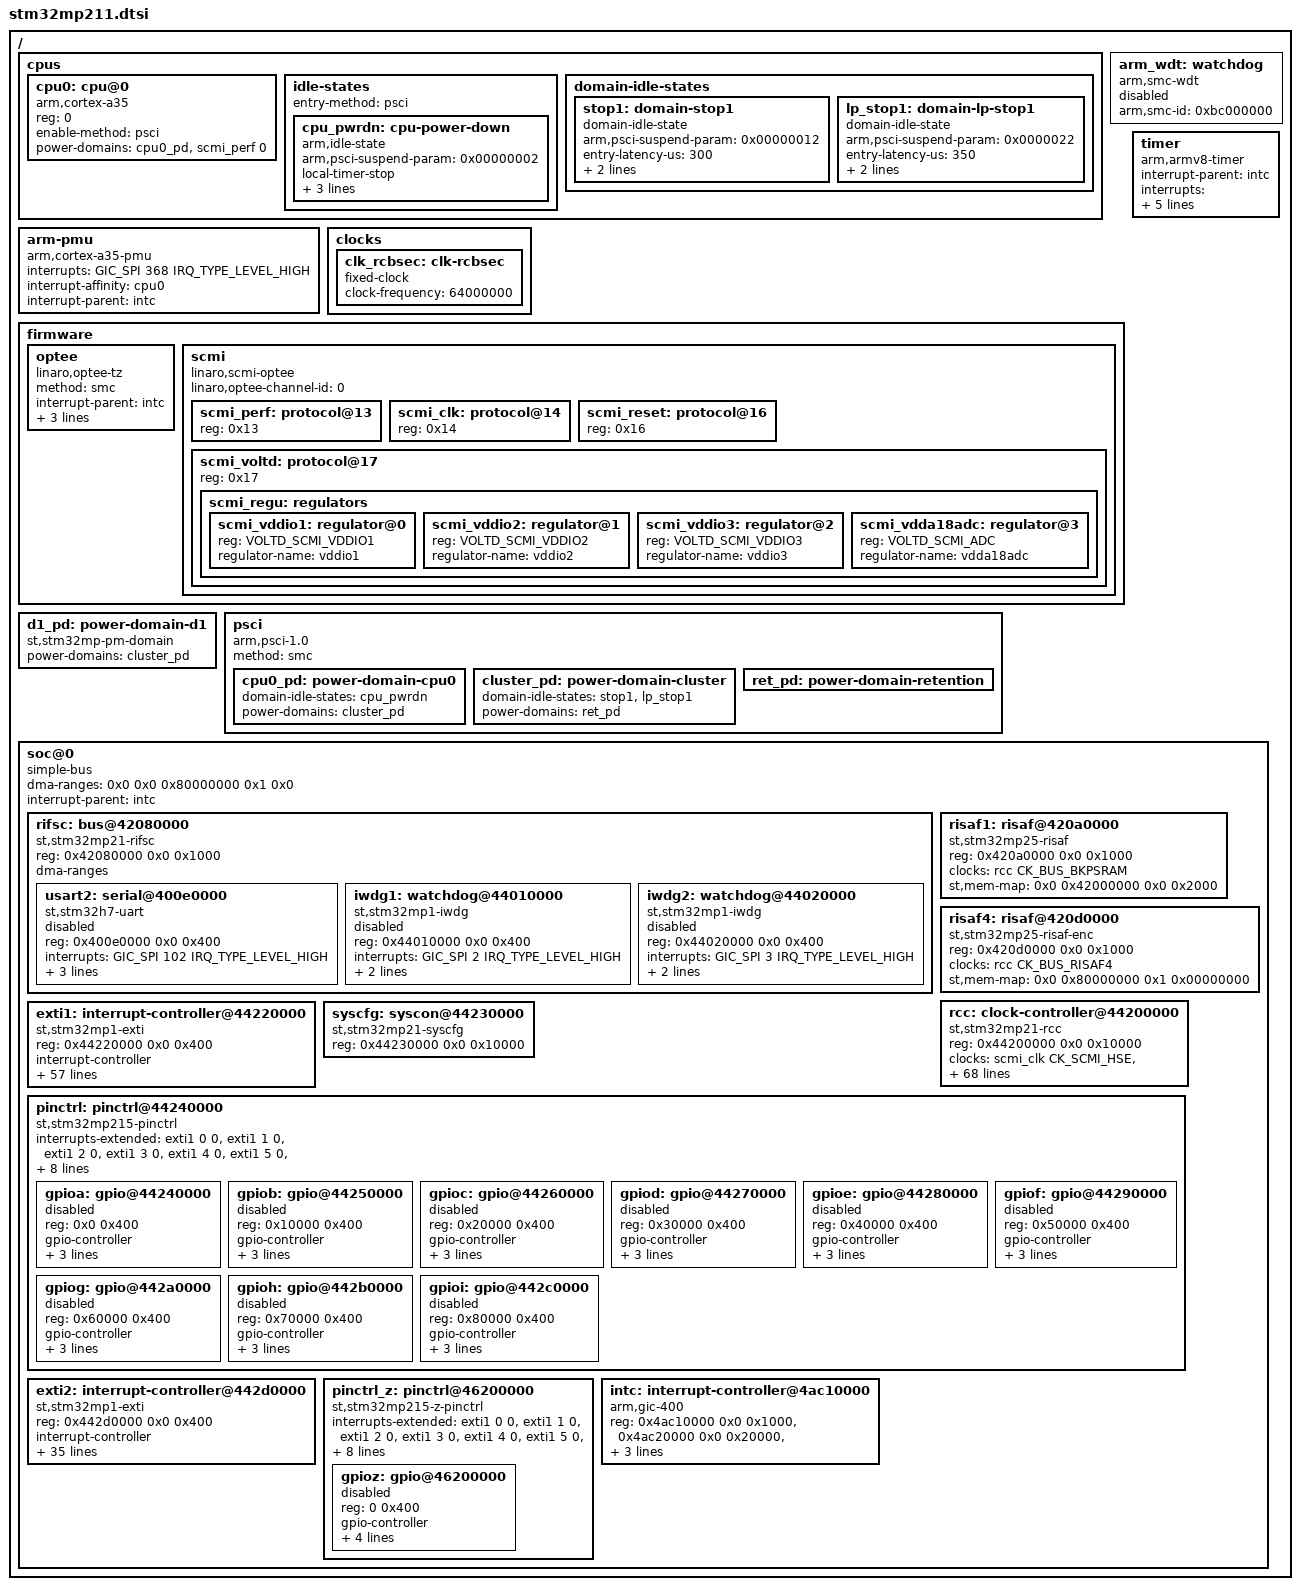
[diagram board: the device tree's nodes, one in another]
// SPDX-License-Identifier: (GPL-2.0-only OR BSD-3-Clause)
/*
 * Copyright (C) STMicroelectronics 2025 - All Rights Reserved
 * Author: Alexandre Torgue <alexandre.torgue@foss.st.com> for STMicroelectronics.
 */
#include <dt-bindings/clock/st,stm32mp21-rcc.h>
#include <dt-bindings/interrupt-controller/arm-gic.h>
#include <dt-bindings/regulator/st,stm32mp21-regulator.h>
#include <dt-bindings/reset/st,stm32mp21-rcc.h>

/ {
	#address-cells = <2>;
	#size-cells = <2>;

	cpus {
		#address-cells = <1>;
		#size-cells = <0>;

		cpu0: cpu@0 {
			compatible = "arm,cortex-a35";
			reg = <0>;
			device_type = "cpu";
			enable-method = "psci";
			power-domains = <&cpu0_pd>, <&scmi_perf 0>;
			power-domain-names = "psci", "perf";
		};

		idle-states {
			entry-method = "psci";

			cpu_pwrdn: cpu-power-down {

				compatible = "arm,idle-state";
				arm,psci-suspend-param = <0x00000002>;
				local-timer-stop;
				entry-latency-us = <150>;
				exit-latency-us = <200>;
				min-residency-us = <1000>;
			};
		};

		domain-idle-states {
			stop1: domain-stop1 {
				compatible = "domain-idle-state";
				arm,psci-suspend-param = <0x00000012>;
				entry-latency-us = <300>;
				exit-latency-us = <500>;
				min-residency-us = <1500>;
			};

			lp_stop1: domain-lp-stop1 {
				compatible = "domain-idle-state";
				arm,psci-suspend-param = <0x0000022>;
				entry-latency-us = <350>;
				exit-latency-us = <600>;
				min-residency-us = <2000>;
			};
		};
	};

	arm-pmu {
		compatible = "arm,cortex-a35-pmu";
		interrupts = <GIC_SPI 368 IRQ_TYPE_LEVEL_HIGH>;
		interrupt-affinity = <&cpu0>;
		interrupt-parent = <&intc>;
	};

	arm_wdt: watchdog {
		compatible = "arm,smc-wdt";
		arm,smc-id = <0xbc000000>;
		status = "disabled";
	};

	clocks {
		clk_rcbsec: clk-rcbsec {
			#clock-cells = <0>;
			compatible = "fixed-clock";
			clock-frequency = <64000000>;
		};
	};

	firmware {
		optee: optee {
			compatible = "linaro,optee-tz";
			method = "smc";
			interrupt-parent = <&intc>;
			interrupts = <GIC_PPI 15 (GIC_CPU_MASK_SIMPLE(1) | IRQ_TYPE_LEVEL_LOW)>;
			interrupt-controller;
			#interrupt-cells = <1>;
		};

		scmi: scmi {
			compatible = "linaro,scmi-optee";
			#address-cells = <1>;
			#size-cells = <0>;
			linaro,optee-channel-id = <0>;

			scmi_perf: protocol@13 {
				reg = <0x13>;
				#power-domain-cells = <1>;
			};

			scmi_clk: protocol@14 {
				reg = <0x14>;
				#clock-cells = <1>;
			};

			scmi_reset: protocol@16 {
				reg = <0x16>;
				#reset-cells = <1>;
			};

			scmi_voltd: protocol@17 {
				reg = <0x17>;

				scmi_regu: regulators {
					#address-cells = <1>;
					#size-cells = <0>;

					scmi_vddio1: regulator@0 {
						reg = <VOLTD_SCMI_VDDIO1>;
						regulator-name = "vddio1";
					};
					scmi_vddio2: regulator@1 {
						reg = <VOLTD_SCMI_VDDIO2>;
						regulator-name = "vddio2";
					};
					scmi_vddio3: regulator@2 {
						reg = <VOLTD_SCMI_VDDIO3>;
						regulator-name = "vddio3";
					};
					scmi_vdda18adc: regulator@3 {
						reg = <VOLTD_SCMI_ADC>;
						regulator-name = "vdda18adc";
					};
				};
			};
		};
	};

	d1_pd: power-domain-d1 {
		compatible = "st,stm32mp-pm-domain";
		#power-domain-cells = <0>;
		power-domains = <&cluster_pd>;
	};

	psci: psci {
		compatible = "arm,psci-1.0";
		method = "smc";

		cpu0_pd: power-domain-cpu0 {
			#power-domain-cells = <0>;
			domain-idle-states = <&cpu_pwrdn>;
			power-domains = <&cluster_pd>;
		};

		cluster_pd: power-domain-cluster {
			#power-domain-cells = <0>;
			domain-idle-states = <&stop1>, <&lp_stop1>;
			power-domains = <&ret_pd>;
		};

		ret_pd: power-domain-retention {
			#power-domain-cells = <0>;
		};
	};

	timer {
		compatible = "arm,armv8-timer";
		interrupt-parent = <&intc>;
		interrupts = <GIC_PPI 13 (GIC_CPU_MASK_SIMPLE(1) | IRQ_TYPE_LEVEL_LOW)>,
			     <GIC_PPI 14 (GIC_CPU_MASK_SIMPLE(1) | IRQ_TYPE_LEVEL_LOW)>,
			     <GIC_PPI 11 (GIC_CPU_MASK_SIMPLE(1) | IRQ_TYPE_LEVEL_LOW)>,
			     <GIC_PPI 10 (GIC_CPU_MASK_SIMPLE(1) | IRQ_TYPE_LEVEL_LOW)>;
		arm,no-tick-in-suspend;
	};

	soc@0 {
		compatible = "simple-bus";
		ranges = <0x0 0x0 0x0 0x0 0x80000000>;
		dma-ranges = <0x0 0x0 0x80000000 0x1 0x0>;
		interrupt-parent = <&intc>;
		#address-cells = <1>;
		#size-cells = <2>;

		rifsc: bus@42080000 {
			compatible = "st,stm32mp21-rifsc", "simple-bus";
			reg = <0x42080000 0x0 0x1000>;
			#address-cells = <1>;
			#size-cells = <2>;
			#access-controller-cells = <1>;
			ranges;
			dma-ranges;

			usart2: serial@400e0000 {
				compatible = "st,stm32h7-uart";
				reg = <0x400e0000 0x0 0x400>;
				interrupts = <GIC_SPI 102 IRQ_TYPE_LEVEL_HIGH>;
				clocks = <&rcc CK_KER_USART2>;
				access-controllers = <&rifsc 32>;
				power-domains = <&d1_pd>;
				status = "disabled";
			};

			iwdg1: watchdog@44010000 {
				compatible = "st,stm32mp1-iwdg";
				reg = <0x44010000 0x0 0x400>;
				interrupts = <GIC_SPI 2 IRQ_TYPE_LEVEL_HIGH>;
				clocks = <&rcc CK_BUS_IWDG1>, <&scmi_clk CK_SCMI_LSI>;
				clock-names = "pclk", "lsi";
				access-controllers = <&rifsc 100>;
				status = "disabled";
			};

			iwdg2: watchdog@44020000 {
				compatible = "st,stm32mp1-iwdg";
				reg = <0x44020000 0x0 0x400>;
				interrupts = <GIC_SPI 3 IRQ_TYPE_LEVEL_HIGH>;
				clocks = <&rcc CK_BUS_IWDG2>, <&scmi_clk CK_SCMI_LSI>;
				clock-names = "pclk", "lsi";
				access-controllers = <&rifsc 101>;
				status = "disabled";
			};
		};

		risaf1: risaf@420a0000 {
			compatible = "st,stm32mp25-risaf";
			reg = <0x420a0000 0x0 0x1000>;
			clocks = <&rcc CK_BUS_BKPSRAM>;
			st,mem-map = <0x0 0x42000000 0x0 0x2000>;
		};

		risaf4: risaf@420d0000 {
			compatible = "st,stm32mp25-risaf-enc";
			reg = <0x420d0000 0x0 0x1000>;
			clocks = <&rcc CK_BUS_RISAF4>;
			st,mem-map = <0x0 0x80000000 0x1 0x00000000>;
		};

		rcc: clock-controller@44200000 {
			compatible = "st,stm32mp21-rcc";
			reg = <0x44200000 0x0 0x10000>;
			#clock-cells = <1>;
			#reset-cells = <1>;
			clocks =
				<&scmi_clk CK_SCMI_HSE>,
				<&scmi_clk CK_SCMI_HSI>,
				<&scmi_clk CK_SCMI_MSI>,
				<&scmi_clk CK_SCMI_LSE>,
				<&scmi_clk CK_SCMI_LSI>,
				<&scmi_clk CK_SCMI_HSE_DIV2>,
				<&scmi_clk CK_SCMI_ICN_HS_MCU>,
				<&scmi_clk CK_SCMI_ICN_LS_MCU>,
				<&scmi_clk CK_SCMI_ICN_SDMMC>,
				<&scmi_clk CK_SCMI_ICN_DDR>,
				<&scmi_clk CK_SCMI_ICN_DISPLAY>,
				<&scmi_clk CK_SCMI_ICN_HSL>,
				<&scmi_clk CK_SCMI_ICN_NIC>,
				<&scmi_clk CK_SCMI_FLEXGEN_07>,
				<&scmi_clk CK_SCMI_FLEXGEN_08>,
				<&scmi_clk CK_SCMI_FLEXGEN_09>,
				<&scmi_clk CK_SCMI_FLEXGEN_10>,
				<&scmi_clk CK_SCMI_FLEXGEN_11>,
				<&scmi_clk CK_SCMI_FLEXGEN_12>,
				<&scmi_clk CK_SCMI_FLEXGEN_13>,
				<&scmi_clk CK_SCMI_FLEXGEN_14>,
				<&scmi_clk CK_SCMI_FLEXGEN_16>,
				<&scmi_clk CK_SCMI_FLEXGEN_17>,
				<&scmi_clk CK_SCMI_FLEXGEN_18>,
				<&scmi_clk CK_SCMI_FLEXGEN_19>,
				<&scmi_clk CK_SCMI_FLEXGEN_20>,
				<&scmi_clk CK_SCMI_FLEXGEN_21>,
				<&scmi_clk CK_SCMI_FLEXGEN_22>,
				<&scmi_clk CK_SCMI_FLEXGEN_23>,
				<&scmi_clk CK_SCMI_FLEXGEN_24>,
				<&scmi_clk CK_SCMI_FLEXGEN_25>,
				<&scmi_clk CK_SCMI_FLEXGEN_26>,
				<&scmi_clk CK_SCMI_FLEXGEN_27>,
				<&scmi_clk CK_SCMI_FLEXGEN_29>,
				<&scmi_clk CK_SCMI_FLEXGEN_30>,
				<&scmi_clk CK_SCMI_FLEXGEN_31>,
				<&scmi_clk CK_SCMI_FLEXGEN_33>,
				<&scmi_clk CK_SCMI_FLEXGEN_36>,
				<&scmi_clk CK_SCMI_FLEXGEN_37>,
				<&scmi_clk CK_SCMI_FLEXGEN_38>,
				<&scmi_clk CK_SCMI_FLEXGEN_39>,
				<&scmi_clk CK_SCMI_FLEXGEN_40>,
				<&scmi_clk CK_SCMI_FLEXGEN_41>,
				<&scmi_clk CK_SCMI_FLEXGEN_42>,
				<&scmi_clk CK_SCMI_FLEXGEN_43>,
				<&scmi_clk CK_SCMI_FLEXGEN_44>,
				<&scmi_clk CK_SCMI_FLEXGEN_45>,
				<&scmi_clk CK_SCMI_FLEXGEN_46>,
				<&scmi_clk CK_SCMI_FLEXGEN_47>,
				<&scmi_clk CK_SCMI_FLEXGEN_48>,
				<&scmi_clk CK_SCMI_FLEXGEN_50>,
				<&scmi_clk CK_SCMI_FLEXGEN_51>,
				<&scmi_clk CK_SCMI_FLEXGEN_52>,
				<&scmi_clk CK_SCMI_FLEXGEN_53>,
				<&scmi_clk CK_SCMI_FLEXGEN_54>,
				<&scmi_clk CK_SCMI_FLEXGEN_55>,
				<&scmi_clk CK_SCMI_FLEXGEN_56>,
				<&scmi_clk CK_SCMI_FLEXGEN_57>,
				<&scmi_clk CK_SCMI_FLEXGEN_58>,
				<&scmi_clk CK_SCMI_FLEXGEN_61>,
				<&scmi_clk CK_SCMI_FLEXGEN_62>,
				<&scmi_clk CK_SCMI_FLEXGEN_63>,
				<&scmi_clk CK_SCMI_ICN_APB1>,
				<&scmi_clk CK_SCMI_ICN_APB2>,
				<&scmi_clk CK_SCMI_ICN_APB3>,
				<&scmi_clk CK_SCMI_ICN_APB4>,
				<&scmi_clk CK_SCMI_ICN_APB5>,
				<&scmi_clk CK_SCMI_ICN_APBDBG>,
				<&scmi_clk CK_SCMI_TIMG1>,
				<&scmi_clk CK_SCMI_TIMG2>;
			access-controllers = <&rifsc 156>;
		};

		exti1: interrupt-controller@44220000 {
			compatible = "st,stm32mp1-exti";
			reg = <0x44220000 0x0 0x400>;
			interrupt-controller;
			#interrupt-cells = <2>;
			power-domains = <&ret_pd>;
			interrupts-extended =
				<&intc GIC_SPI 268 IRQ_TYPE_LEVEL_HIGH>,	/* EXTI_0 */
				<&intc GIC_SPI 269 IRQ_TYPE_LEVEL_HIGH>,
				<&intc GIC_SPI 270 IRQ_TYPE_LEVEL_HIGH>,
				<&intc GIC_SPI 271 IRQ_TYPE_LEVEL_HIGH>,
				<&intc GIC_SPI 272 IRQ_TYPE_LEVEL_HIGH>,
				<&intc GIC_SPI 273 IRQ_TYPE_LEVEL_HIGH>,
				<&intc GIC_SPI 274 IRQ_TYPE_LEVEL_HIGH>,
				<&intc GIC_SPI 275 IRQ_TYPE_LEVEL_HIGH>,
				<&intc GIC_SPI 276 IRQ_TYPE_LEVEL_HIGH>,
				<&intc GIC_SPI 277 IRQ_TYPE_LEVEL_HIGH>,
				<&intc GIC_SPI 278 IRQ_TYPE_LEVEL_HIGH>,	/* EXTI_10 */
				<&intc GIC_SPI 279 IRQ_TYPE_LEVEL_HIGH>,
				<&intc GIC_SPI 280 IRQ_TYPE_LEVEL_HIGH>,
				<&intc GIC_SPI 281 IRQ_TYPE_LEVEL_HIGH>,
				<&intc GIC_SPI 282 IRQ_TYPE_LEVEL_HIGH>,
				<&intc GIC_SPI 283 IRQ_TYPE_LEVEL_HIGH>,
				<&intc GIC_SPI 0   IRQ_TYPE_LEVEL_HIGH>,
				<&intc GIC_SPI 1   IRQ_TYPE_LEVEL_HIGH>,
				<&intc GIC_SPI 211 IRQ_TYPE_LEVEL_HIGH>,
				<&intc GIC_SPI 210 IRQ_TYPE_LEVEL_HIGH>,
				<0>,						/* EXTI_20 */
				<&intc GIC_SPI 95  IRQ_TYPE_LEVEL_HIGH>,
				<&intc GIC_SPI 97  IRQ_TYPE_LEVEL_HIGH>,
				<&intc GIC_SPI 124 IRQ_TYPE_LEVEL_HIGH>,
				<0>,
				<0>,
				<&intc GIC_SPI 101 IRQ_TYPE_LEVEL_HIGH>,
				<&intc GIC_SPI 102 IRQ_TYPE_LEVEL_HIGH>,
				<&intc GIC_SPI 103 IRQ_TYPE_LEVEL_HIGH>,
				<&intc GIC_SPI 123 IRQ_TYPE_LEVEL_HIGH>,
				<&intc GIC_SPI 113 IRQ_TYPE_LEVEL_HIGH>,	/* EXTI_30 */
				<&intc GIC_SPI 114 IRQ_TYPE_LEVEL_HIGH>,
				<&intc GIC_SPI 135 IRQ_TYPE_LEVEL_HIGH>,
				<0>,
				<0>,
				<0>,
				<&intc GIC_SPI 99  IRQ_TYPE_LEVEL_HIGH>,
				<&intc GIC_SPI 100 IRQ_TYPE_LEVEL_HIGH>,
				<&intc GIC_SPI 112 IRQ_TYPE_LEVEL_HIGH>,
				<&intc GIC_SPI 137 IRQ_TYPE_LEVEL_HIGH>,
				<&intc GIC_SPI 138 IRQ_TYPE_LEVEL_HIGH>,	/* EXTI_40 */
				<&intc GIC_SPI 139 IRQ_TYPE_LEVEL_HIGH>,
				<0>,
				<&intc GIC_SPI 150 IRQ_TYPE_LEVEL_HIGH>,
				<&intc GIC_SPI 158 IRQ_TYPE_LEVEL_HIGH>,
				<0>,
				<0>,
				<&intc GIC_SPI 149 IRQ_TYPE_LEVEL_HIGH>,
				<&intc GIC_SPI 180 IRQ_TYPE_LEVEL_HIGH>,
				<0>,
				<0>,						/* EXTI_50 */
				<0>,
				<0>,
				<0>,
				<0>,
				<0>,
				<0>,
				<0>,
				<0>,
				<&intc GIC_SPI 152 IRQ_TYPE_LEVEL_HIGH>,
				<0>,						/* EXTI_60 */
				<&intc GIC_SPI 154 IRQ_TYPE_LEVEL_HIGH>,
				<0>,
				<0>,
				<&intc GIC_SPI 185 IRQ_TYPE_LEVEL_HIGH>,
				<0>,
				<0>,
				<&intc GIC_SPI 9   IRQ_TYPE_LEVEL_HIGH>,
				<&intc GIC_SPI 118 IRQ_TYPE_LEVEL_HIGH>,
				<0>,
				<&intc GIC_SPI 121 IRQ_TYPE_LEVEL_HIGH>,	/* EXTI_70 */
				<0>,
				<&intc GIC_SPI 188 IRQ_TYPE_LEVEL_HIGH>,
				<&intc GIC_SPI 172 IRQ_TYPE_LEVEL_HIGH>,
				<&intc GIC_SPI 96  IRQ_TYPE_LEVEL_HIGH>,
				<&intc GIC_SPI 98  IRQ_TYPE_LEVEL_HIGH>,
				<&intc GIC_SPI 125 IRQ_TYPE_LEVEL_HIGH>,
				<&intc GIC_SPI 205 IRQ_TYPE_LEVEL_HIGH>,
				<&intc GIC_SPI 206 IRQ_TYPE_LEVEL_HIGH>,
				<&intc GIC_SPI 207 IRQ_TYPE_LEVEL_HIGH>;
		};

		syscfg: syscon@44230000 {
			compatible = "st,stm32mp21-syscfg", "syscon";
			reg = <0x44230000 0x0 0x10000>;
		};

		pinctrl: pinctrl@44240000 {
			compatible = "st,stm32mp215-pinctrl";
			ranges = <0 0x44240000 0x80400>;
			#address-cells = <1>;
			#size-cells = <1>;
			interrupts-extended =
				<&exti1  0 0>, <&exti1  1 0>, <&exti1  2 0>, <&exti1  3 0>,
				<&exti1  4 0>, <&exti1  5 0>, <&exti1  6 0>, <&exti1  7 0>,
				<&exti1  8 0>, <&exti1  9 0>, <&exti1 10 0>, <&exti1 11 0>,
				<&exti1 12 0>, <&exti1 13 0>, <&exti1 14 0>, <&exti1 15 0>,
				<&exti2  0 0>, <&exti2  1 0>, <&exti2  2 0>, <&exti2  3 0>,
				<&exti2  4 0>, <&exti2  5 0>, <&exti2  6 0>, <&exti2  7 0>,
				<&exti2  8 0>, <&exti2  9 0>, <&exti2 10 0>, <&exti2 11 0>,
				<&exti2 12 0>, <&exti2 13 0>, <&exti2 14 0>, <&exti2 15 0>;

			gpioa: gpio@44240000 {
				reg = <0x0 0x400>;
				gpio-controller;
				#gpio-cells = <2>;
				interrupt-controller;
				#interrupt-cells = <2>;
				clocks = <&scmi_clk CK_SCMI_GPIOA>;
				st,bank-name = "GPIOA";
				status = "disabled";
			};

			gpiob: gpio@44250000 {
				reg = <0x10000 0x400>;
				gpio-controller;
				#gpio-cells = <2>;
				interrupt-controller;
				#interrupt-cells = <2>;
				clocks = <&scmi_clk CK_SCMI_GPIOB>;
				st,bank-name = "GPIOB";
				status = "disabled";
			};

			gpioc: gpio@44260000 {
				reg = <0x20000 0x400>;
				gpio-controller;
				#gpio-cells = <2>;
				interrupt-controller;
				#interrupt-cells = <2>;
				clocks = <&scmi_clk CK_SCMI_GPIOC>;
				st,bank-name = "GPIOC";
				status = "disabled";
			};

			gpiod: gpio@44270000 {
				reg = <0x30000 0x400>;
				gpio-controller;
				#gpio-cells = <2>;
				interrupt-controller;
				#interrupt-cells = <2>;
				clocks = <&scmi_clk CK_SCMI_GPIOD>;
				st,bank-name = "GPIOD";
				status = "disabled";
			};

			gpioe: gpio@44280000 {
				reg = <0x40000 0x400>;
				gpio-controller;
				#gpio-cells = <2>;
				interrupt-controller;
				#interrupt-cells = <2>;
				clocks = <&scmi_clk CK_SCMI_GPIOE>;
				st,bank-name = "GPIOE";
				status = "disabled";
			};

			gpiof: gpio@44290000 {
				reg = <0x50000 0x400>;
				gpio-controller;
				#gpio-cells = <2>;
				interrupt-controller;
				#interrupt-cells = <2>;
				clocks = <&scmi_clk CK_SCMI_GPIOF>;
				st,bank-name = "GPIOF";
				status = "disabled";
			};

			gpiog: gpio@442a0000 {
				reg = <0x60000 0x400>;
				gpio-controller;
				#gpio-cells = <2>;
				interrupt-controller;
				#interrupt-cells = <2>;
				clocks = <&scmi_clk CK_SCMI_GPIOG>;
				st,bank-name = "GPIOG";
				status = "disabled";
			};

			gpioh: gpio@442b0000 {
				reg = <0x70000 0x400>;
				gpio-controller;
				#gpio-cells = <2>;
				interrupt-controller;
				#interrupt-cells = <2>;
				clocks = <&scmi_clk CK_SCMI_GPIOH>;
				st,bank-name = "GPIOH";
				status = "disabled";
			};

			gpioi: gpio@442c0000 {
				reg = <0x80000 0x400>;
				gpio-controller;
				#gpio-cells = <2>;
				interrupt-controller;
				#interrupt-cells = <2>;
				clocks = <&scmi_clk CK_SCMI_GPIOI>;
				st,bank-name = "GPIOI";
				status = "disabled";
			};
		};

		exti2: interrupt-controller@442d0000 {
			compatible = "st,stm32mp1-exti";
			reg = <0x442d0000 0x0 0x400>;
			interrupt-controller;
			#interrupt-cells = <2>;
			interrupts-extended =
				<&intc GIC_SPI 15  IRQ_TYPE_LEVEL_HIGH>,	/* EXTI_0 */
				<&intc GIC_SPI 16  IRQ_TYPE_LEVEL_HIGH>,
				<&intc GIC_SPI 17  IRQ_TYPE_LEVEL_HIGH>,
				<&intc GIC_SPI 18  IRQ_TYPE_LEVEL_HIGH>,
				<&intc GIC_SPI 19  IRQ_TYPE_LEVEL_HIGH>,
				<&intc GIC_SPI 20  IRQ_TYPE_LEVEL_HIGH>,
				<&intc GIC_SPI 21  IRQ_TYPE_LEVEL_HIGH>,
				<&intc GIC_SPI 22  IRQ_TYPE_LEVEL_HIGH>,
				<&intc GIC_SPI 23  IRQ_TYPE_LEVEL_HIGH>,
				<&intc GIC_SPI 24  IRQ_TYPE_LEVEL_HIGH>,
				<&intc GIC_SPI 25  IRQ_TYPE_LEVEL_HIGH>,	/* EXTI_10 */
				<&intc GIC_SPI 26  IRQ_TYPE_LEVEL_HIGH>,
				<&intc GIC_SPI 27  IRQ_TYPE_LEVEL_HIGH>,
				<&intc GIC_SPI 28  IRQ_TYPE_LEVEL_HIGH>,
				<&intc GIC_SPI 29  IRQ_TYPE_LEVEL_HIGH>,
				<&intc GIC_SPI 30  IRQ_TYPE_LEVEL_HIGH>,
				<&intc GIC_SPI 10  IRQ_TYPE_LEVEL_HIGH>,
				<&intc GIC_SPI 11  IRQ_TYPE_LEVEL_HIGH>,
				<0>,
				<0>,
				<0>,						/* EXTI_20 */
				<&intc GIC_SPI 12  IRQ_TYPE_LEVEL_HIGH>,
				<&intc GIC_SPI 13  IRQ_TYPE_LEVEL_HIGH>,
				<0>,
				<0>,
				<0>,
				<&intc GIC_SPI 136 IRQ_TYPE_LEVEL_HIGH>,
				<0>,
				<0>,
				<&intc GIC_SPI 181 IRQ_TYPE_LEVEL_HIGH>,
				<&intc GIC_SPI 182 IRQ_TYPE_LEVEL_HIGH>,	/* EXTI_30 */
				<&intc GIC_SPI 183 IRQ_TYPE_LEVEL_HIGH>,
				<0>,
				<0>,
				<0>,
				<&intc GIC_SPI 5   IRQ_TYPE_LEVEL_HIGH>,
				<&intc GIC_SPI 4   IRQ_TYPE_LEVEL_HIGH>,
				<&intc GIC_SPI 6   IRQ_TYPE_LEVEL_HIGH>,
				<0>,
				<&intc GIC_SPI 2   IRQ_TYPE_LEVEL_HIGH>,
				<&intc GIC_SPI 3   IRQ_TYPE_LEVEL_HIGH>,	/* EXTI_40 */
				<0>,
				<0>,
				<0>,
				<0>,
				<0>,
				<0>,
				<0>,
				<0>,
				<&intc GIC_SPI 201 IRQ_TYPE_LEVEL_HIGH>,
				<0>,						/* EXTI_50 */
				<&intc GIC_SPI 202 IRQ_TYPE_LEVEL_HIGH>,
				<&intc GIC_SPI 203 IRQ_TYPE_LEVEL_HIGH>,
				<&intc GIC_SPI 204 IRQ_TYPE_LEVEL_HIGH>;
		};

		pinctrl_z: pinctrl@46200000 {
			compatible = "st,stm32mp215-z-pinctrl";
			ranges = <0 0x46200000 0x400>;
			#address-cells = <1>;
			#size-cells = <1>;
			interrupts-extended =
				<&exti1  0 0>, <&exti1  1 0>, <&exti1  2 0>, <&exti1  3 0>,
				<&exti1  4 0>, <&exti1  5 0>, <&exti1  6 0>, <&exti1  7 0>,
				<&exti1  8 0>, <&exti1  9 0>, <&exti1 10 0>, <&exti1 11 0>,
				<&exti1 12 0>, <&exti1 13 0>, <&exti1 14 0>, <&exti1 15 0>,
				<&exti2  0 0>, <&exti2  1 0>, <&exti2  2 0>, <&exti2  3 0>,
				<&exti2  4 0>, <&exti2  5 0>, <&exti2  6 0>, <&exti2  7 0>,
				<&exti2  8 0>, <&exti2  9 0>, <&exti2 10 0>, <&exti2 11 0>,
				<&exti2 12 0>, <&exti2 13 0>, <&exti2 14 0>, <&exti2 15 0>;

			gpioz: gpio@46200000 {
				reg = <0 0x400>;
				gpio-controller;
				#gpio-cells = <2>;
				interrupt-controller;
				#interrupt-cells = <2>;
				clocks = <&scmi_clk CK_SCMI_GPIOZ>;
				st,bank-name = "GPIOZ";
				st,bank-ioport = <11>;
				status = "disabled";
			};
		};

		intc: interrupt-controller@4ac10000 {
			compatible = "arm,gic-400";
			reg = <0x4ac10000 0x0 0x1000>,
			      <0x4ac20000 0x0 0x20000>,
			      <0x4ac40000 0x0 0x20000>,
			      <0x4ac60000 0x0 0x20000>;
			#interrupt-cells = <3>;
			interrupt-controller;
		};
	};
};
